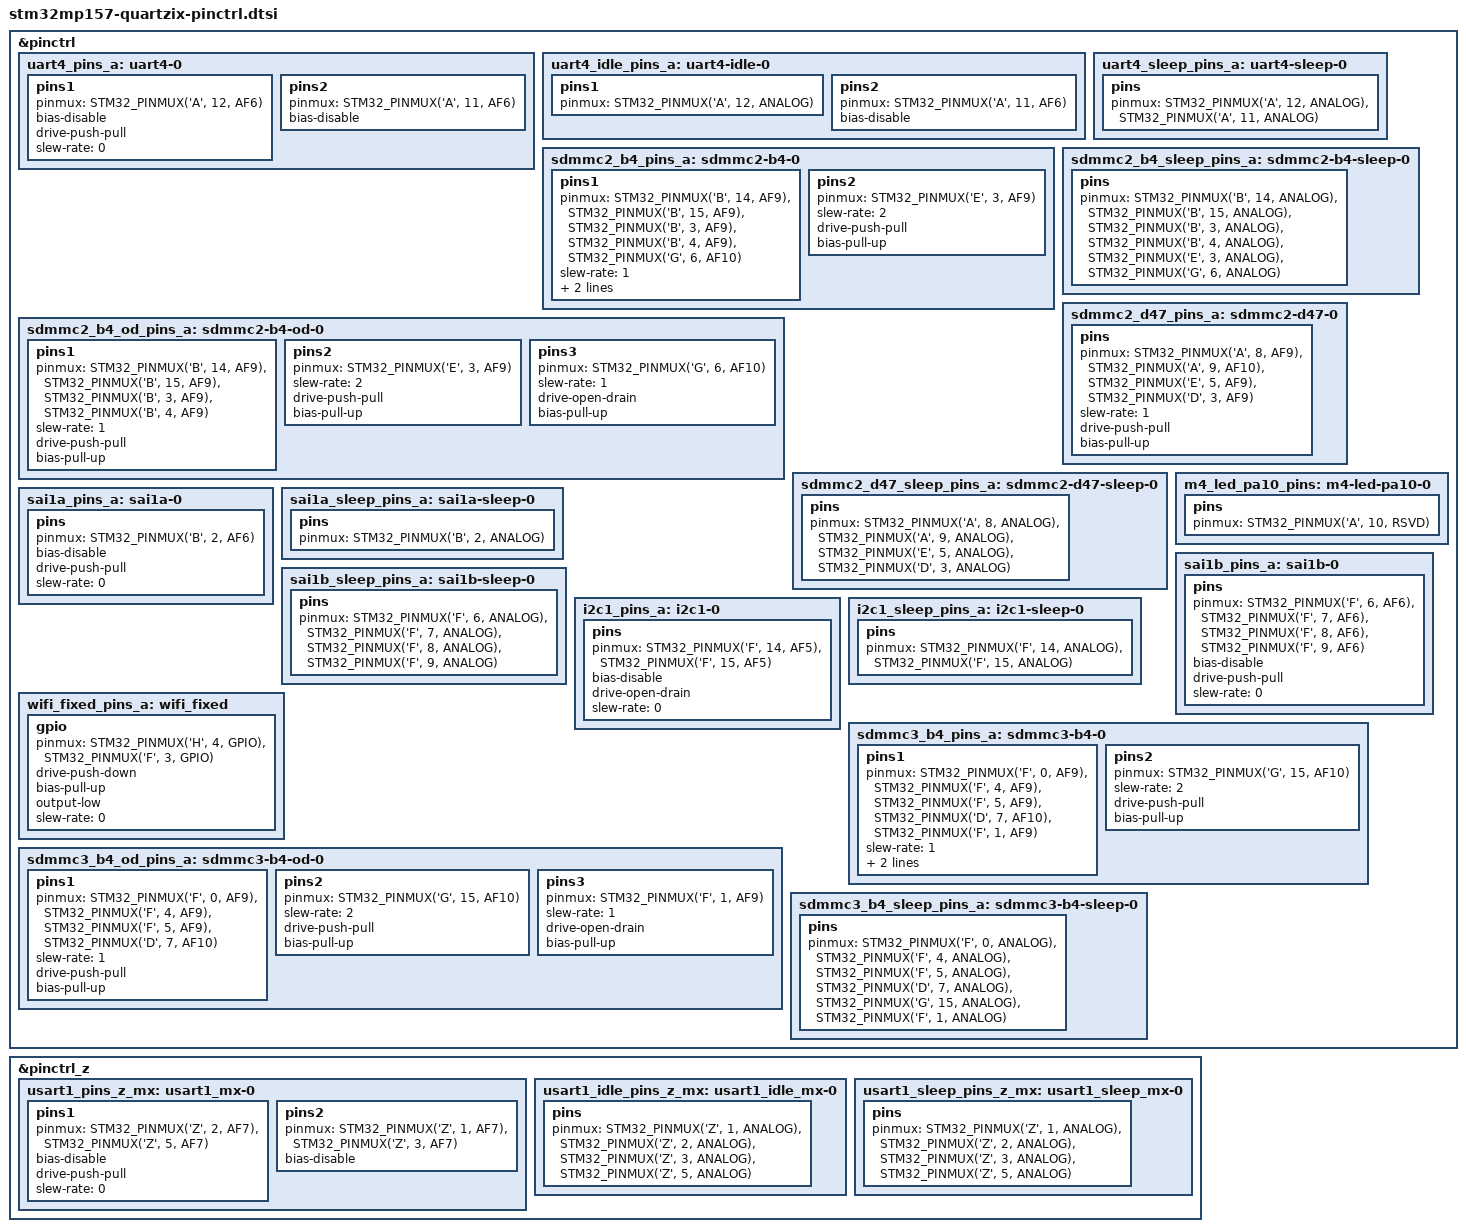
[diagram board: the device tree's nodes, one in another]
// SPDX-License-Identifier: (GPL-2.0+ OR BSD-3-Clause)
/*
 * Copyright (C) STMicroelectronics 2017 - All Rights Reserved
 * Author: Ludovic Barre <ludovic.barre@st.com> for STMicroelectronics.
 * Modified for Quartzix board configuration
 */
#include <dt-bindings/pinctrl/stm32-pinfunc.h>

/*
 * Pin control configuration for STM32MP157 Quartzix board
 * This file contains pin multiplexing definitions for various peripherals
 */

&pinctrl {
	uart4_pins_a: uart4-0 {
		pins1 {
			pinmux = <STM32_PINMUX('A', 12, AF6)>; /* UART4_TX */
			bias-disable;
			drive-push-pull;
			slew-rate = <0>;
		};
		pins2 {
			pinmux = <STM32_PINMUX('A', 11, AF6)>; /* UART4_RX */
			bias-disable;
		};
	};
	uart4_idle_pins_a: uart4-idle-0 {
		pins1 {
			pinmux = <STM32_PINMUX('A', 12, ANALOG)>; /* UART4_TX */
		};
		pins2 {
			pinmux = <STM32_PINMUX('A', 11, AF6)>; /* UART4_RX */
			bias-disable;
		};
	};

	uart4_sleep_pins_a: uart4-sleep-0 {
		pins {
			pinmux = <STM32_PINMUX('A', 12, ANALOG)>, /* UART4_TX */
				 <STM32_PINMUX('A', 11, ANALOG)>; /* UART4_RX */
		};
	};

	sdmmc2_b4_pins_a: sdmmc2-b4-0 {
		pins1 {
				pinmux = <STM32_PINMUX('B', 14, AF9)>, /* SDMMC2_D0 */
							<STM32_PINMUX('B', 15, AF9)>, /* SDMMC2_D1 */
							<STM32_PINMUX('B', 3, AF9)>, /* SDMMC2_D2 */
							<STM32_PINMUX('B', 4, AF9)>, /* SDMMC2_D3 */
							<STM32_PINMUX('G', 6, AF10)>; /* SDMMC2_CMD */
				slew-rate = <1>;
				drive-push-pull;
				bias-pull-up;
		};
		pins2 {
				pinmux = <STM32_PINMUX('E', 3, AF9)>; /* SDMMC2_CK */
				slew-rate = <2>;
				drive-push-pull;
				bias-pull-up;
		};
	};

	sdmmc2_b4_od_pins_a: sdmmc2-b4-od-0 {
		pins1 {
				pinmux = <STM32_PINMUX('B', 14, AF9)>, /* SDMMC2_D0 */
							<STM32_PINMUX('B', 15, AF9)>, /* SDMMC2_D1 */
							<STM32_PINMUX('B', 3, AF9)>, /* SDMMC2_D2 */
							<STM32_PINMUX('B', 4, AF9)>; /* SDMMC2_D3 */
				slew-rate = <1>;
				drive-push-pull;
				bias-pull-up;
		};
		pins2 {
				pinmux = <STM32_PINMUX('E', 3, AF9)>; /* SDMMC2_CK */
				slew-rate = <2>;
				drive-push-pull;
				bias-pull-up;
		};
		pins3 {
				pinmux = <STM32_PINMUX('G', 6, AF10)>; /* SDMMC2_CMD */
				slew-rate = <1>;
				drive-open-drain;
				bias-pull-up;
		};
	};

	sdmmc2_b4_sleep_pins_a: sdmmc2-b4-sleep-0 {
		pins {
				pinmux = <STM32_PINMUX('B', 14, ANALOG)>, /* SDMMC2_D0 */
							<STM32_PINMUX('B', 15, ANALOG)>, /* SDMMC2_D1 */
							<STM32_PINMUX('B', 3, ANALOG)>, /* SDMMC2_D2 */
							<STM32_PINMUX('B', 4, ANALOG)>, /* SDMMC2_D3 */
							<STM32_PINMUX('E', 3, ANALOG)>, /* SDMMC2_CK */
							<STM32_PINMUX('G', 6, ANALOG)>; /* SDMMC2_CMD */
		};
	};


	sdmmc2_d47_pins_a: sdmmc2-d47-0 {
			pins {
					pinmux = <STM32_PINMUX('A', 8, AF9)>, /* SDMMC2_D4 */
								<STM32_PINMUX('A', 9, AF10)>, /* SDMMC2_D5 */
								<STM32_PINMUX('E', 5, AF9)>, /* SDMMC2_D6 */
								<STM32_PINMUX('D', 3, AF9)>; /* SDMMC2_D7 */
					slew-rate = <1>;
					drive-push-pull;
					bias-pull-up;
			};
	};

	sdmmc2_d47_sleep_pins_a: sdmmc2-d47-sleep-0 {
			pins {
					pinmux = <STM32_PINMUX('A', 8, ANALOG)>, /* SDMMC2_D4 */
								<STM32_PINMUX('A', 9, ANALOG)>, /* SDMMC2_D5 */
								<STM32_PINMUX('E', 5, ANALOG)>, /* SDMMC2_D6 */
								<STM32_PINMUX('D', 3, ANALOG)>; /* SDMMC2_D7 */
			};
	};

	/* M4 LED pin - PA10 reserved for Cortex-M4 */
	m4_led_pa10_pins: m4-led-pa10-0 {
		pins {
			pinmux = <STM32_PINMUX('A', 10, RSVD)>;
		};
	};

	/* SAI1_A: playback data to WM8960 DACDAT (PB2 -> WM8960 pin 10) */
	sai1a_pins_a: sai1a-0 {
		pins {
			pinmux = <STM32_PINMUX('B', 2, AF6)>; /* SAI1_SD_A */
			bias-disable;
			drive-push-pull;
			slew-rate = <0>;
		};
	};
	sai1a_sleep_pins_a: sai1a-sleep-0 {
		pins {
			pinmux = <STM32_PINMUX('B', 2, ANALOG)>;
		};
	};

	/* SAI1_B: clocks (MCLK/BCLK/LRCLK) + ADCDAT from WM8960 (PF6 <- WM8960 pin 8) */
	sai1b_pins_a: sai1b-0 {
		pins {
			pinmux = <STM32_PINMUX('F', 6, AF6)>,  /* SAI1_SD_B */
				 <STM32_PINMUX('F', 7, AF6)>,  /* SAI1_MCLK_B */
				 <STM32_PINMUX('F', 8, AF6)>,  /* SAI1_SCK_B */
				 <STM32_PINMUX('F', 9, AF6)>;  /* SAI1_FS_B */
			bias-disable;
			drive-push-pull;
			slew-rate = <0>;
		};
	};
	sai1b_sleep_pins_a: sai1b-sleep-0 {
		pins {
			pinmux = <STM32_PINMUX('F', 6, ANALOG)>,
				 <STM32_PINMUX('F', 7, ANALOG)>,
				 <STM32_PINMUX('F', 8, ANALOG)>,
				 <STM32_PINMUX('F', 9, ANALOG)>;
		};
	};

	/* I2C1: WM8960 control interface */
	i2c1_pins_a: i2c1-0 {
		pins {
			pinmux = <STM32_PINMUX('F', 14, AF5)>, /* I2C1_SCL */
				 <STM32_PINMUX('F', 15, AF5)>; /* I2C1_SDA */
			bias-disable;
			drive-open-drain;
			slew-rate = <0>;
		};
	};
	i2c1_sleep_pins_a: i2c1-sleep-0 {
		pins {
			pinmux = <STM32_PINMUX('F', 14, ANALOG)>,
				 <STM32_PINMUX('F', 15, ANALOG)>;
		};
	};

	/* WiFi power control GPIOs */
	wifi_fixed_pins_a: wifi_fixed {
		gpio {
			pinmux = <STM32_PINMUX('H', 4, GPIO)>,
				 <STM32_PINMUX('F', 3, GPIO)>;
			drive-push-down;
			bias-pull-up;
			output-low;
			slew-rate = <0>;
		};
	};

	/* SDMMC3 - WiFi SDIO interface */
	sdmmc3_b4_pins_a: sdmmc3-b4-0 {
		pins1 {
			pinmux = <STM32_PINMUX('F', 0, AF9)>,  /* SDMMC3_D0 */
				 <STM32_PINMUX('F', 4, AF9)>,  /* SDMMC3_D1 */
				 <STM32_PINMUX('F', 5, AF9)>,  /* SDMMC3_D2 */
				 <STM32_PINMUX('D', 7, AF10)>, /* SDMMC3_D3 */
				 <STM32_PINMUX('F', 1, AF9)>;  /* SDMMC3_CMD */
			slew-rate = <1>;
			drive-push-pull;
			bias-pull-up;
		};
		pins2 {
			pinmux = <STM32_PINMUX('G', 15, AF10)>; /* SDMMC3_CK */
			slew-rate = <2>;
			drive-push-pull;
			bias-pull-up;
		};
	};

	sdmmc3_b4_od_pins_a: sdmmc3-b4-od-0 {
		pins1 {
			pinmux = <STM32_PINMUX('F', 0, AF9)>,  /* SDMMC3_D0 */
				 <STM32_PINMUX('F', 4, AF9)>,  /* SDMMC3_D1 */
				 <STM32_PINMUX('F', 5, AF9)>,  /* SDMMC3_D2 */
				 <STM32_PINMUX('D', 7, AF10)>; /* SDMMC3_D3 */
			slew-rate = <1>;
			drive-push-pull;
			bias-pull-up;
		};
		pins2 {
			pinmux = <STM32_PINMUX('G', 15, AF10)>; /* SDMMC3_CK */
			slew-rate = <2>;
			drive-push-pull;
			bias-pull-up;
		};
		pins3 {
			pinmux = <STM32_PINMUX('F', 1, AF9)>; /* SDMMC3_CMD */
			slew-rate = <1>;
			drive-open-drain;
			bias-pull-up;
		};
	};

	sdmmc3_b4_sleep_pins_a: sdmmc3-b4-sleep-0 {
		pins {
			pinmux = <STM32_PINMUX('F', 0, ANALOG)>,  /* SDMMC3_D0 */
				 <STM32_PINMUX('F', 4, ANALOG)>,  /* SDMMC3_D1 */
				 <STM32_PINMUX('F', 5, ANALOG)>,  /* SDMMC3_D2 */
				 <STM32_PINMUX('D', 7, ANALOG)>,  /* SDMMC3_D3 */
				 <STM32_PINMUX('G', 15, ANALOG)>, /* SDMMC3_CK */
				 <STM32_PINMUX('F', 1, ANALOG)>;  /* SDMMC3_CMD */
		};
	};
};

/* Bluetooth UART pins (GPIO Z bank) */
&pinctrl_z {
	usart1_pins_z_mx: usart1_mx-0 {
		pins1 {
			pinmux = <STM32_PINMUX('Z', 2, AF7)>, /* USART1_TX */
				 <STM32_PINMUX('Z', 5, AF7)>; /* USART1_RTS */
			bias-disable;
			drive-push-pull;
			slew-rate = <0>;
		};
		pins2 {
			pinmux = <STM32_PINMUX('Z', 1, AF7)>, /* USART1_RX */
				 <STM32_PINMUX('Z', 3, AF7)>; /* USART1_CTS */
			bias-disable;
		};
	};

	usart1_idle_pins_z_mx: usart1_idle_mx-0 {
		pins {
			pinmux = <STM32_PINMUX('Z', 1, ANALOG)>, /* USART1_RX */
				 <STM32_PINMUX('Z', 2, ANALOG)>, /* USART1_TX */
				 <STM32_PINMUX('Z', 3, ANALOG)>, /* USART1_CTS */
				 <STM32_PINMUX('Z', 5, ANALOG)>; /* USART1_RTS */
		};
	};

	usart1_sleep_pins_z_mx: usart1_sleep_mx-0 {
		pins {
			pinmux = <STM32_PINMUX('Z', 1, ANALOG)>, /* USART1_RX */
				 <STM32_PINMUX('Z', 2, ANALOG)>, /* USART1_TX */
				 <STM32_PINMUX('Z', 3, ANALOG)>, /* USART1_CTS */
				 <STM32_PINMUX('Z', 5, ANALOG)>; /* USART1_RTS */
		};
	};
};

